# ATA5832 device description
Architecture: AVR8; Family: megaAVR
Registers are 8-bit, access not given, no defined reset value unless marked. A register's access mark holds for its fields unless they carry their own. Offsets are from the block's base; [hi:lo] are bit positions; {n}, {i} and the like mark numbered series; 'fields as' and 'values as' point back to an identical list.

## SSM
Instances: SSM 0x00
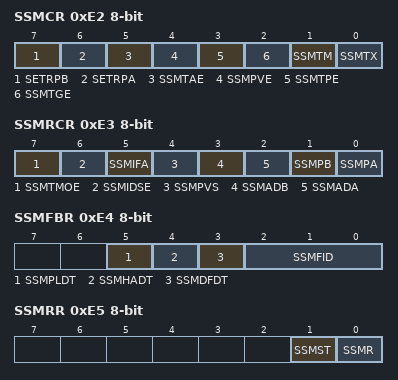
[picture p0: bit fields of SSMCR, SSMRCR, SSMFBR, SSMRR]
0xE2 SSMCR — SSM Control Register
  [7] SETRPB — Sequencer State Machine Enable Transparent Path B
  [6] SETRPA — Sequencer State Machine Enable Transparent Path A
  [5] SSMTAE — Sequencer State Machine Tx Ask-Shaping Enable
  [4] SSMPVE — Sequencer State Machine PV Enable
  [3] SSMTPE — Sequencer State Machine Tx Preemphasis Enable
  [2] SSMTGE — Sequencer State Machine Tx Gauss Enable
  [1] SSMTM — Sequencer State Machine Temperature Measurement
  [0] SSMTX — Sequencer State Machine Tx
0xE3 SSMRCR — SSM Rx Control Register
  [7] SSMTMOE — Sequencer State Machine Transparent Mode Output Enable
  [6] SSMIDSE — Sequencer State Machine ID Scan Enable
  [5] SSMIFA — Sequencer State Machine IF Amplifier Enable
  [4] SSMPVS — Sequencer State Machine Path Valid After SOT
  [3] SSMADB — Sequencer State Machine Antenna Damping Disable Path B
  [2] SSMADA — Sequencer State Machine Antenna Damping Disable Path A
  [1] SSMPB — Sequencer State Machine Path B
  [0] SSMPA — Sequencer State Machine Path A
0xE4 SSMFBR — SSM Filter Bandwidth Register
  [5] SSMPLDT — Sequencer State Machine PLL Lock Delay Time
  [4] SSMHADT — Sequencer State Machine Half Antennadamping Delay Time
  [3] SSMDFDT — Sequencer State Machine Double Filter Delay Time
  [2:0] SSMFID — Sequencer State Machine Filter Delay
0xE5 SSMRR — SSM Run Register
  [1] SSMST — Sequencer State Machine Stop
  [0] SSMR — Sequencer State Machine Run
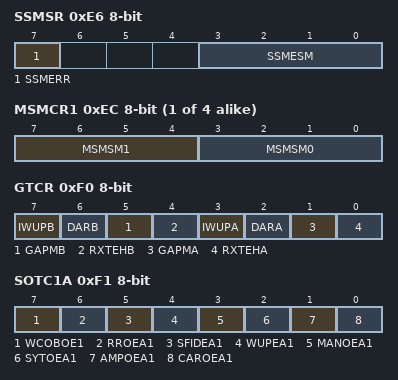
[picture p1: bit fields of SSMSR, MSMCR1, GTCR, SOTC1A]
0xE6 SSMSR — SSM Status Register
  [7] SSMERR — Sequencer State Machine Error
  [3:0] SSMESM — Sequencer State Machine Error State Machine
0xE7 SSMIFR — SSM Interrupt Flag Register
  [0] SSMIF — Sequencer State Machine Interrupt Flag
0xE8 SSMIMR — SSM interrupt mask register
  [0] SSMIM — Sequencer State Machine Interrupt Mask
0xE9 MSMSTR — Master State Machine state register
  [4:0] SSMMST — Sequencer State Machine Master State
0xEA SSMSTR — SSM State Register
  [5:0] SSMSTA — Sequencer State Machine State A
0xEB SSMXSR — SSM extended State Register
  [5:0] SSMSTB — Sequencer State Machine State B
{0xEB+i} MSMCR{i} (i=1..4) — Master State Machine Control Register {i}
  [7:4] MSMSM{2i-1} — Master State Machine SubState Machine Select {2i-1}
    0=NONE_STOP; 1=PLL_EN; 2=PLL_LOCK; 3=RX_DSP_ENABLE; 4=RX_DSP_DISABLE; 5=TX_DSP_ENABLE; 6=TX_DSP_DISABLE; 7=RX_TO_TX; 8=TX_TO_RX; 9=GET_TELEGRAM; 10=SEND_TELEGRAM; 11=SHUT_DOWN; 12=VCO_TUNING; 13=ANTENNA_TUNING
  [3:0] MSMSM{2i-2} — Master State Machine SubState Machine Select {2i-2}
    values as MSMSM{2i-1}
0xF0 GTCR — Get Telegram Control Register
  [7] IWUPB — Intermittent WUP Mode Path B
  [6] DARB — Demodulator Automatic Restart on Path B
  [5] GAPMB — Gap Mode Path B
  [4] RXTEHB — Rx Telegram End Handling Path B
  [3] IWUPA — Intermittent WUP Mode Path A
  [2] DARA — Demodulator Automatic Restart on Path A
  [1] GAPMA — Gap Mode Path A
  [0] RXTEHA — Rx Telegram End Handling Path A
0xF1 SOTC1A — Start Of Telegram Conditions 1 for Path A
  [7] WCOBOE1 — Wake Check OK from path B Ok Enable
  [6] RROEA1 — RSSI Range OK Enable for path A
  [5] SFIDEA1 — Start of Frame IDentifier match Enabled for path A
  [4] WUPEA1 — Wake Up Pattern match Enabled for path A
  [3] MANOEA1 — Manchester Coding Ok Enabled for path A
  [2] SYTOEA1 — Symbol Timing Ok Enabled for path A
  [1] AMPOEA1 — AMPlitude Ok Enabled for path A
  [0] CAROEA1 — CARrier check Ok Enabled for path A
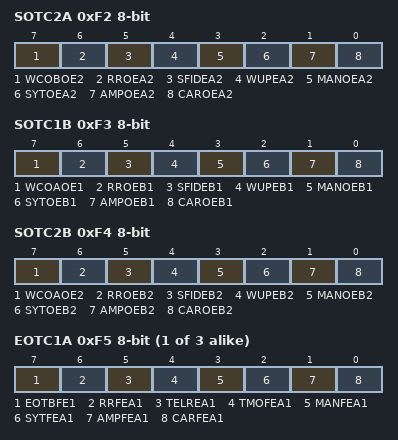
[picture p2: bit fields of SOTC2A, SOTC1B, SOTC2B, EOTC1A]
0xF2 SOTC2A — Start Of Telegram Conditions 2 for Path A
  [7] WCOBOE2 — Wake Check OK from path B Ok Enable
  [6] RROEA2 — RSSI Range OK Enable for path A
  [5] SFIDEA2 — Start of Frame IDentifier match Enabled for path A
  [4] WUPEA2 — Wake Up Pattern match Enabled for path A
  [3] MANOEA2 — Manchester Coding Ok Enabled for path A
  [2] SYTOEA2 — Symbol Timing Ok Enabled for path A
  [1] AMPOEA2 — AMPlitude Ok Enabled for path A
  [0] CAROEA2 — CARrier check Ok Enabled for path A
0xF3 SOTC1B — Start Of Telegram Conditions 1 for Path B
  [7] WCOAOE1 — Wake Check Ok on path B Ok
  [6] RROEB1 — RSSI Range Ok on Path A
  [5] SFIDEB1 — Start of Frame IDentifier match Enabled for path B
  [4] WUPEB1 — Wake Up Pattern match Enabled for path B
  [3] MANOEB1 — Manchester Coding Ok Enabled for path B
  [2] SYTOEB1 — Symbol Timing Ok Enabled for path B
  [1] AMPOEB1 — AMPlitude Ok Enabled for path B
  [0] CAROEB1 — CARrier check Ok Enabled for path B
0xF4 SOTC2B — Start Of Telegram Conditions 2 for Path B
  [7] WCOAOE2 — Wake Check Ok on path B Ok
  [6] RROEB2 — RSSI Range Ok on Path A
  [5] SFIDEB2 — Start of Frame IDentifier match Enabled for path B
  [4] WUPEB2 — Wake Up Pattern match Enabled for path B
  [3] MANOEB2 — Manchester Coding Ok Enabled for path B
  [2] SYTOEB2 — Symbol Timing Ok Enabled for path B
  [1] AMPOEB2 — AMPlitude Ok Enabled for path B
  [0] CAROEB2 — CARrier check Ok Enabled for path B
{0xF4+i} EOTC{i}A (i=1..3) — End Of Telegram Conditions {i} for Path A
  [7] EOTBFE{i} — End Of Telegram on Path B Fail Enable
  [6] RRFEA{i} — RSSI Range Fail Enable on Path A
  [5] TELREA{i} — Telegram Length Reached Enable on Path A
  [4] TMOFEA{i} — Time-Out Fail Enable on Path A
  [3] MANFEA{i} — MANchester Coding Failed Enable for Path A
  [2] SYTFEA{i} — SYmbol Timing check Failed Enable for Path A
  [1] AMPFEA{i} — AMPlitude Failed Enable for path A
  [0] CARFEA{i} — CARrier check Failed Enable for path A
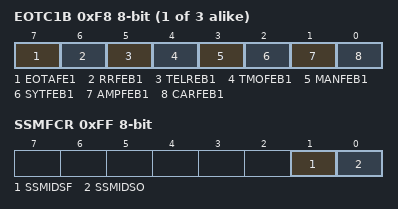
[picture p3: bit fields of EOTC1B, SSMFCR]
{0xF7+i} EOTC{i}B (i=1..3) — End Of Telegram Conditions {i} for Path B
  [7] EOTAFE{i} — End Of Telegram on Path B Fail Enable
  [6] RRFEB{i} — RSSI Range Fail Enable on Path B
  [5] TELREB{i} — Telegram Length Reached Enable on Path B
  [4] TMOFEB{i} — Time-Out Fail Enable on Path B
  [3] MANFEB{i} — MANchester Coding Failed Enable for Path B
  [2] SYTFEB{i} — SYmbol Timing check Failed Enable for Path B
  [1] AMPFEB{i} — AMPlitude Failed Enable for path B
  [0] CARFEB{i} — CARrier check Failed Enable for path B
0xFB WCOTOA — Wait check ok time out for path A
0xFC WCOTOB — Wait check ok time out for path B
0xFD SOTTOA — Start Of Telegram Time Out for path A
0xFE SOTTOB — Start Of Telegram Time Out for path B
0xFF SSMFCR — SSM Flow Control Register
  [1] SSMIDSF — Sequencer State Machine ID Scan Fail
  [0] SSMIDSO — Sequencer State Machine ID Scan OK
